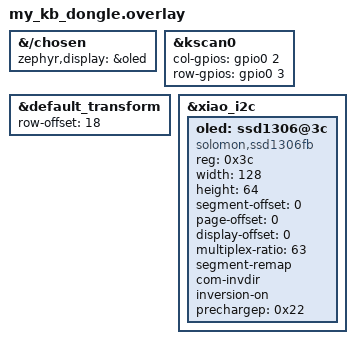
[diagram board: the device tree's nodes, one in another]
#include "my_kb.dtsi"


&{/chosen} {
    zephyr,display = &oled;
};

&kscan0 {
    
    col-gpios =
        <&gpio0 2 GPIO_ACTIVE_HIGH>;

    row-gpios =
        <&gpio0 3 (GPIO_ACTIVE_HIGH | GPIO_PULL_DOWN)>;
};

&default_transform {
    row-offset = <18>;
};


&xiao_i2c {
    status = "okay";
    
    oled: ssd1306@3c {
        compatible = "solomon,ssd1306fb";
        reg = <0x3c>;
        width = <128>;
        height = <64>;
        segment-offset = <0>;
        page-offset = <0>;
        display-offset = <0>;
        multiplex-ratio = <63>;
        segment-remap;
        com-invdir;
        inversion-on;
        prechargep = <0x22>;
    };
}; 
